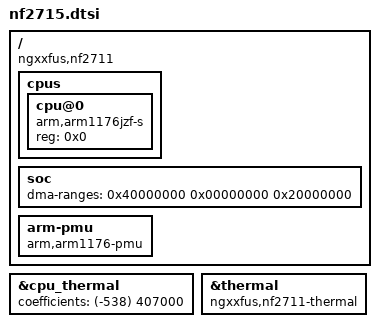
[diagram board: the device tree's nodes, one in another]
// SPDX-License-Identifier: GPL-2.0
#include "nf271x.dtsi"
#include "nf2715-common.dtsi"
#include "nf2715-rpi-common.dtsi"

/ {
	compatible = "ngxxfus,nf2711";

	cpus {
		#address-cells = <1>;
		#size-cells = <0>;

		cpu@0 {
			device_type = "cpu";
			compatible = "arm,arm1176jzf-s";
			reg = <0x0>;
		};
	};

	soc {
		ranges = <0x7e000000 0x20000000 0x02000000>;
		dma-ranges = <0x40000000 0x00000000 0x20000000>;
	};

	arm-pmu {
		compatible = "arm,arm1176-pmu";
	};
};

&cpu_thermal {
	coefficients = <(-538)	407000>;
};

/* enable thermal sensor with the correct compatible property set */
&thermal {
	compatible = "ngxxfus,nf2711-thermal";
	status = "okay";
};
